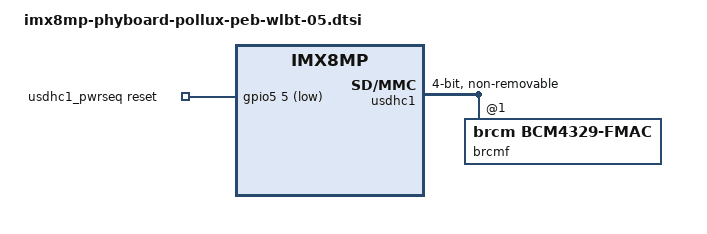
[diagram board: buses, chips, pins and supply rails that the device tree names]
// SPDX-License-Identifier: GPL-2.0
/*
 * Copyright (C) 2021 PHYTEC Messtechnik GmbH
 * Author: Christian Hemp <c.hemp@phytec.de>
 *
 */

/ {
	usdhc1_pwrseq: pwr_seq {
		compatible = "mmc-pwrseq-simple";
		reset-gpios = <&gpio5 5 GPIO_ACTIVE_LOW>;
		post-power-on-delay-ms = <100>;
		power-off-delay-us = <60>;
	};
};

&usdhc1 {
	#address-cells = <1>;
	#size-cells = <0>;
	pinctrl-names = "default";
	pinctrl-0 = <&pinctrl_usdhc1>;
	bus-width = <4>;
	non-removable;
	no-1-8-v;
	mmc-pwrseq = <&usdhc1_pwrseq>;
	wifi-host;
	status = "okay";

	brcmf: wifi@1 {
		reg = <1>;
		compatible = "brcm,bcm4329-fmac";
	};
};

&iomuxc {
	pinctrl_usdhc1: usdhc1grp {
		fsl,pins = <
			MX8MP_IOMUXC_SD1_CLK__USDHC1_CLK        0x190
			MX8MP_IOMUXC_SD1_CMD__USDHC1_CMD        0x1d0
			MX8MP_IOMUXC_SD1_DATA0__USDHC1_DATA0    0x1d0
			MX8MP_IOMUXC_SD1_DATA1__USDHC1_DATA1    0x1d0
			MX8MP_IOMUXC_SD1_DATA2__USDHC1_DATA2    0x1d0
			MX8MP_IOMUXC_SD1_DATA3__USDHC1_DATA3    0x1d0
			MX8MP_IOMUXC_SPDIF_EXT_CLK__GPIO5_IO05	0x1d0
		>;
	};
};
